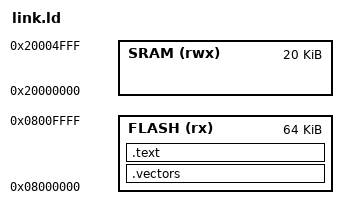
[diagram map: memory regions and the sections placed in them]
MEMORY
{
  FLASH (rx)  : ORIGIN = 0x08000000, LENGTH = 64K
  SRAM  (rwx) : ORIGIN = 0x20000000, LENGTH = 20K
}

ENTRY(Reset_Handler)

SECTIONS
{
  .vectors :
  {
    . = ALIGN(4);
    KEEP(*(.vectors))
    . = ALIGN(4);
  } > FLASH

  .text :
  {
    . = ALIGN(4);
    *(.text*)
    *(.rodata*)
    . = ALIGN(4);
  } > FLASH

  _estack = ORIGIN(SRAM) + LENGTH(SRAM);
}
